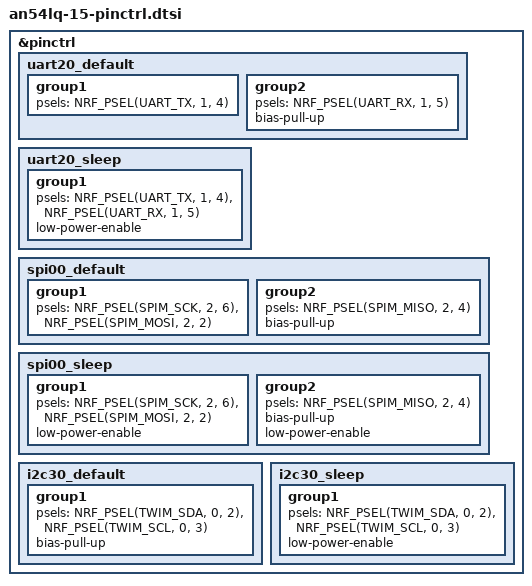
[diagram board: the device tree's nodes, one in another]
/*
 * Copyright (c) 2025 SlimeVR contributors
 * SPDX-License-Identifier: MIT
 *
 * AN54LQ-15 (nRF54L15 module) pin assignments for SlimeVR-Tracker-nRF.
 *
 * Default wiring (adjust via overlay for your specific board):
 *   UART20  : TX=P1.4, RX=P1.5
 *   SPI00   : SCK=P2.6, MOSI=P2.2, MISO=P2.4  (high-speed SPI for IMU)
 *   I2C30   : SDA=P0.2, SCL=P0.3               (optional, for magnetometer)
 */

&pinctrl {
	/omit-if-no-ref/ uart20_default: uart20_default {
		group1 {
			psels = <NRF_PSEL(UART_TX, 1, 4)>;
		};
		group2 {
			psels = <NRF_PSEL(UART_RX, 1, 5)>;
			bias-pull-up;
		};
	};

	/omit-if-no-ref/ uart20_sleep: uart20_sleep {
		group1 {
			psels = <NRF_PSEL(UART_TX, 1, 4)>,
				<NRF_PSEL(UART_RX, 1, 5)>;
			low-power-enable;
		};
	};

	/omit-if-no-ref/ spi00_default: spi00_default {
		group1 {
			psels = <NRF_PSEL(SPIM_SCK, 2, 6)>,
				<NRF_PSEL(SPIM_MOSI, 2, 2)>;
		};
		group2 {
			psels = <NRF_PSEL(SPIM_MISO, 2, 4)>;
			bias-pull-up;
		};
	};

	/omit-if-no-ref/ spi00_sleep: spi00_sleep {
		group1 {
			psels = <NRF_PSEL(SPIM_SCK, 2, 6)>,
				<NRF_PSEL(SPIM_MOSI, 2, 2)>;
			low-power-enable;
		};
		group2 {
			psels = <NRF_PSEL(SPIM_MISO, 2, 4)>;
			bias-pull-up;
			low-power-enable;
		};
	};

	/omit-if-no-ref/ i2c30_default: i2c30_default {
		group1 {
			psels = <NRF_PSEL(TWIM_SDA, 0, 2)>,
				<NRF_PSEL(TWIM_SCL, 0, 3)>;
			bias-pull-up;
		};
	};

	/omit-if-no-ref/ i2c30_sleep: i2c30_sleep {
		group1 {
			psels = <NRF_PSEL(TWIM_SDA, 0, 2)>,
				<NRF_PSEL(TWIM_SCL, 0, 3)>;
			low-power-enable;
		};
	};
};
